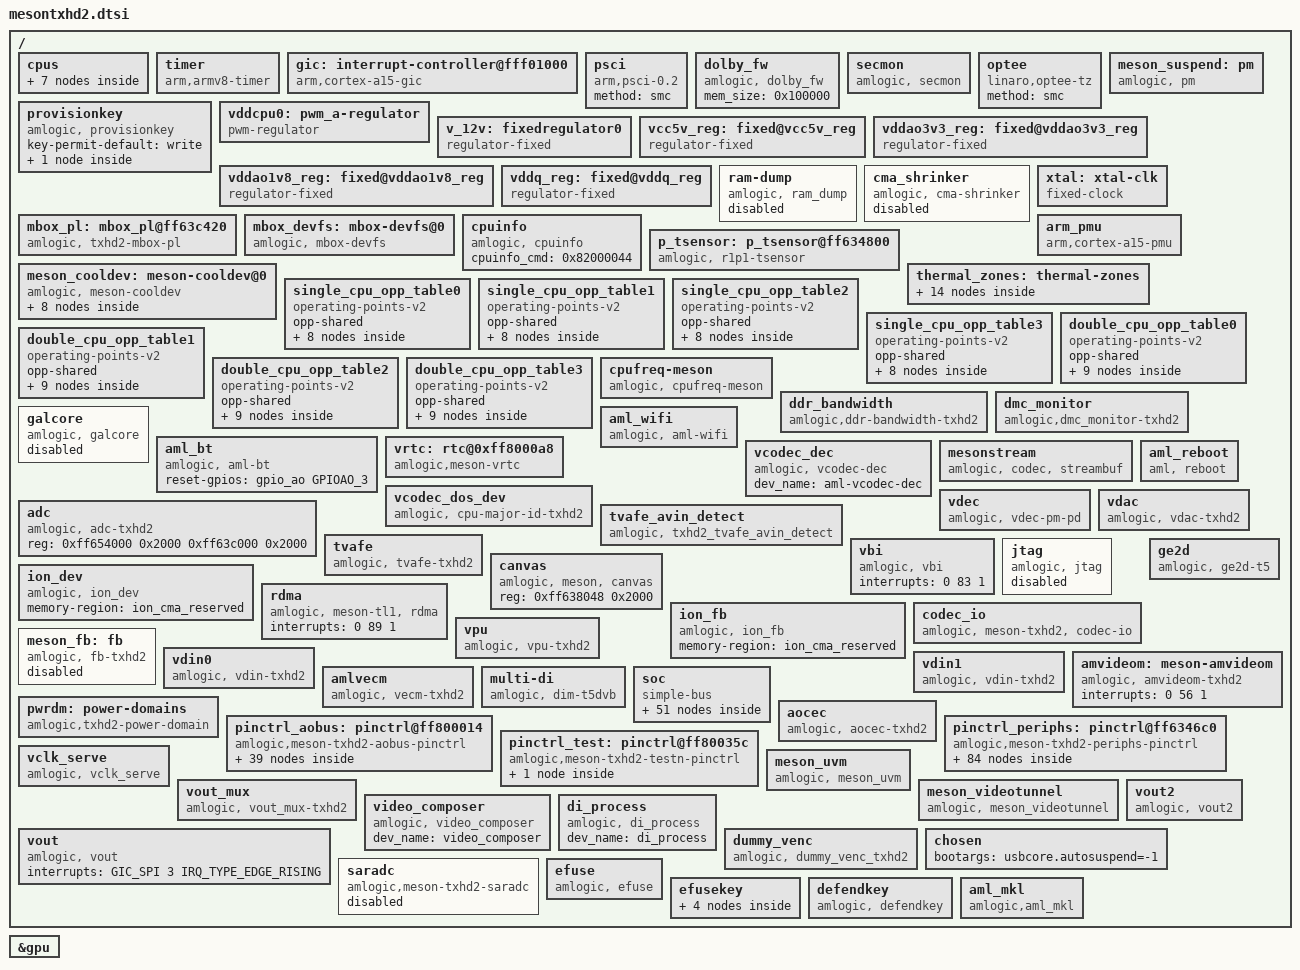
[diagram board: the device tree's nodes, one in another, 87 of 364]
// SPDX-License-Identifier: (GPL-2.0+ OR MIT)
/*
 * Copyright (c) 2021 Amlogic, Inc. All rights reserved.
 */

#include <dt-bindings/interrupt-controller/irq.h>
#include <dt-bindings/interrupt-controller/arm-gic.h>
#include <dt-bindings/power/txhd2-pd.h>
#include <dt-bindings/clock/txhd2-clkc.h>
#include <dt-bindings/clock/txhd2-aoclkc.h>
#include <dt-bindings/mailbox/txhd2-mbox.h>
#include <dt-bindings/gpio/gpio.h>
#include <dt-bindings/gpio/meson-txhd2-gpio.h>
#include <dt-bindings/pwm/pwm.h>
#include <dt-bindings/pwm/meson.h>
#include <dt-bindings/input/input.h>
#include <dt-bindings/input/meson_ir.h>
#include <dt-bindings/iio/adc/amlogic-saradc.h>
#include "meson-ir-map.dtsi"
#include <dt-bindings/thermal/thermal.h>
#include <dt-bindings/hwspinlock/amlogic,hwspinlock.h>
#include <dt-bindings/reset/amlogic,meson-txhd2-reset.h>
#include "mesongxbb-gpu-mali450.dtsi"

/ {
	cpus:cpus {
		#address-cells = <1>;
		#size-cells = <0>;

		CPU0:cpu@0 {
			device_type = "cpu";
			compatible = "arm,cortex-a53","arm,armv8";
			reg = <0x0>;
			enable-method = "psci";
			cpu-idle-states = <&CPU_SLEEP_0 &SYSTEM_SLEEP_0>;
			#cooling-cells = <2>;
			clocks = <&clkc CLKID_CPU_CLK>,
				<&clkc CLKID_CPU_CLK_DYN>,
				<&clkc CLKID_SYS_PLL>;
			clock-names = "core_clk",
				"low_freq_clk_parent",
				"high_freq_clk_parent";
			multi_tables_available;
			cpu-supply = <&vddcpu0>;
			voltage-tolerance = <0>;
			clock-latency = <50000>;
			dynamic-power-coefficient = <230>;
		};

		CPU1:cpu@1{
			device_type = "cpu";
			compatible = "arm,cortex-a53","arm,armv8";
			reg = <0x1>;
			enable-method = "psci";
			cpu-idle-states = <&CPU_SLEEP_0 &SYSTEM_SLEEP_0>;
			#cooling-cells = <2>;
//			clocks = <&clkc CLKID_CPU_CLK>,
//				<&clkc CLKID_CPU_DYN_CLK>,
//				<&clkc CLKID_SYS1_PLL>;
//			clock-names = "core_clk",
//				"low_freq_clk_parent",
//				"high_freq_clk_parent";
			multi_tables_available;
			voltage-tolerance = <0>;
			clock-latency = <50000>;
			dynamic-power-coefficient = <230>;
		};

		CPU2:cpu@2 {
			device_type = "cpu";
			compatible = "arm,cortex-a53","arm,armv8";
			reg = <0x2>;
			enable-method = "psci";
			cpu-idle-states = <&CPU_SLEEP_0 &SYSTEM_SLEEP_0>;
			#cooling-cells = <2>;
//			clocks = <&clkc CLKID_CPU_CLK>,
//				<&clkc CLKID_CPU_DYN_CLK>,
//				<&clkc CLKID_SYS1_PLL>;
//			clock-names = "core_clk",
//				"low_freq_clk_parent",
//				"high_freq_clk_parent";
			multi_tables_available;
			voltage-tolerance = <0>;
			clock-latency = <50000>;
			dynamic-power-coefficient = <230>;
		};

		CPU3:cpu@3 {
			device_type = "cpu";
			compatible = "arm,cortex-a53","arm,armv8";
			reg = <0x3>;
			enable-method = "psci";
			cpu-idle-states = <&CPU_SLEEP_0 &SYSTEM_SLEEP_0>;
			#cooling-cells = <2>;
//			clocks = <&clkc CLKID_CPU_CLK>,
//				<&clkc CLKID_CPU_DYN_CLK>,
//				<&clkc CLKID_SYS1_PLL>;
//			clock-names = "core_clk",
//				"low_freq_clk_parent",
//				"high_freq_clk_parent";
			multi_tables_available;
			voltage-tolerance = <0>;
			clock-latency = <50000>;
		};

		idle-states {
			entry-method = "arm,psci-0.2";
			CPU_SLEEP_0: cpu-sleep-0 {
					compatible = "arm,idle-state";
					arm,psci-suspend-param = <0x0010000>;
					local-timer-stop;
					entry-latency-us = <160>;
					exit-latency-us = <630>;
					min-residency-us = <1700>;
			};
			SYSTEM_SLEEP_0: system-sleep-0 {
					compatible = "arm,idle-state";
					arm,psci-suspend-param = <0x0000000>;
					entry-latency-us = <0x3fffffff>;
					exit-latency-us = <0x40000000>;
					min-residency-us = <0xffffffff>;
			};
		};
	};

	timer {
		compatible = "arm,armv8-timer";
		interrupts = <GIC_PPI 13 0xff08>,
				<GIC_PPI 14 0xff08>,
				<GIC_PPI 11 0xff08>,
				<GIC_PPI 10 0xff08>;
	};

	gic: interrupt-controller@fff01000 {
		compatible = "arm,cortex-a15-gic", "arm,cortex-a9-gic";
		#interrupt-cells = <3>;
		#address-cells = <0>;
		interrupt-controller;
		reg = <0xffc01000 0x1000>,
		      <0xffc02000 0x0100>;
		interrupts = <GIC_PPI 9 0xf04>;
	};

	psci {
		compatible = "arm,psci-0.2";
		method = "smc";
	};

	dolby_fw: dolby_fw {
		compatible = "amlogic, dolby_fw";
		mem_size = <0x100000>;
		status = "okay";
	};

	secmon {
		compatible = "amlogic, secmon";
		memory-region = <&secmon_reserved>;
		in_base_func = <0x82000020>;
		out_base_func = <0x82000021>;
		inout_size_func = <0x8200002a>;
		reserve_mem_size = <0x00300000>;
	};

	optee {
		compatible = "linaro,optee-tz";
		method = "smc";
	};

	provisionkey {
		compatible = "amlogic, provisionkey";
		status = "okay";
		key-permit-default = "write";
		//new key not need add dts if started with KEY_PROVISION_
		KEY_PROVISION_XXX { };
		//test_my_added_keyname { };
	};//End provisionkey

	meson_suspend:pm {
		compatible = "amlogic, pm";
		status = "okay";
		device_name = "aml_pm";
		extend_resume_reason;
		reg = <0xff8000a8 0x4>, /*SYSCTRL_STATUS_REG2*/
			<0xff6345cc 0x4>; /*SYSCTRL_STICKY_REG3*/
	};

	vddcpu0: pwm_a-regulator {
		compatible = "pwm-regulator";
		pwms = <&pwm_ab MESON_PWM_0 1500 0>;
		regulator-name = "vddcpu0";
		regulator-min-microvolt = <790000>;
		regulator-max-microvolt = <1150000>;
		regulator-always-on;
		max-duty-cycle = <1500>;
		/* Voltage Duty-Cycle */
		voltage-table = //<1150000 0>,//low:0x0024
				<1140000 0>,//0022
				<1130000 6>,//10021
				<1120000 8>,//20020
				<1110000 11>,//3001f
				<1100000 14>,//4001e
				<1090000 17>,//5001d
				<1080000 19>,//0006001c//
				<1070000 22>,//7001b
				<1060000 25>,//8001a
				<1050000 28>,//90019
				<1040000 31>,//a0018
				<1030000 33>,//b0017
				<1020000 36>,//c0016
				<1010000 39>,//0x00d00015
				<1000000 42>,//0x00e00014
				<990000 44>,//0x00f00013
				<980000 47>,//0x00100012
				<970000 50>,//0x00110011
				<960000 53>,//0x00120010
				<950000 56>,//0x0013000f
				<940000 58>,//0x0014000E
				<930000 61>,//0x0015000d
				<920000 64>,//0x0016000c
				<910000 67>,//0x0017000b
				<900000 69>,//0x0018000a
				<890000 72>,//0x00190009
				<880000 75>,//0x001a0008
				<870000 78>,//0x001b0007
				<860000 81>,//0x001c0006
				<850000 83>,//0x001d0005
				<840000 86>,//1e0004
				<830000 89>,//1f0003
				<820000 92>,//200002
				<810000 94>,//210001
				<800000 100>;//220000
				//<790000 100>;//high:0x240000
		status = "okay";
	};

	v_12v: fixedregulator0 {
		compatible = "regulator-fixed";
		regulator-name = "POWER_12V";
		regulator-min-microvolt = <12000000>;
		regulator-max-microvolt = <12000000>;
		regulator-boot-on;
		regulator-always-on;
	};

	vcc5v_reg: fixed@vcc5v_reg{
		vin-supply = <&v_12v>;
		compatible = "regulator-fixed";
		regulator-name = "VCC5V";
		regulator-min-microvolt = <5000000>;
		regulator-max-microvolt = <5000000>;
		gpio = <&gpio_ao GPIOAO_10 GPIO_ACTIVE_HIGH>;
		enable-active-high;
		regulator-boot-on;
		regulator-always-on;
	};

	vddao3v3_reg: fixed@vddao3v3_reg{
		vin-supply = <&v_12v>;
		compatible = "regulator-fixed";
		regulator-name = "VDDAO_3V3";
		regulator-min-microvolt = <3300000>;
		regulator-max-microvolt = <3300000>;
		regulator-boot-on;
		regulator-always-on;
	};

	vddao1v8_reg: fixed@vddao1v8_reg{
		vin-supply = <&vddao3v3_reg>;
		compatible = "regulator-fixed";
		regulator-name = "VDDAO_1V8";
		regulator-min-microvolt = <1800000>;
		regulator-max-microvolt = <1800000>;
		regulator-boot-on;
		regulator-always-on;
	};

	vddq_reg: fixed@vddq_reg{
		compatible = "regulator-fixed";
		vin-supply = <&v_12v>;
		regulator-name = "VDDQ";
		regulator-min-microvolt = <1218000>;
		regulator-max-microvolt = <1218000>;
		gpio = <&gpio_test GPIO_TEST_N GPIO_ACTIVE_HIGH>;
		enable-active-high;
		regulator-boot-on;
		regulator-always-on;
	};

	ram-dump {
		compatible = "amlogic, ram_dump";
		status = "disabled";
		reg = <0xFF6345E0   0x4>;
		reg-names = "SYSCTRL_STICKY_REG6";
		store_device = "data";
	};

	cma_shrinker: cma_shrinker {
		compatible = "amlogic, cma-shrinker";
		status = "disabled";
		adj  = <0 100 200 250 900 950>;
		free = <8192 12288 16384 24576 28672 32768>;
	};

	xtal: xtal-clk {
		compatible = "fixed-clock";
		clock-frequency = <24000000>;
		clock-output-names = "xtal";
		#clock-cells = <0>;
	};

	mbox_pl: mbox_pl@ff63c420 {
		status = "okay";
		compatible = "amlogic, txhd2-mbox-pl";
		reg = <0xfffc7400 0x200>, /*ao rx buf */
		      <0xff63c41C 0x4>,   /*ao rx set addr*/
		      <0xff63c424 0x4>,   /*ao rx clr addr*/
		      <0xff63c420 0x4>,   /*ao rx sts addr*/
		      <0xfffc7600 0x200>, /*ao tx buf */
		      <0xff63c428 0x4>,   /*ao tx set addr*/
		      <0xff63c430 0x4>,   /*ao tx clr addr*/
		      <0xff63c42C 0x4>;   /*ao tx sts addr*/
		interrupts = <GIC_SPI 210 IRQ_TYPE_EDGE_RISING>,
			     <GIC_SPI 136 IRQ_TYPE_EDGE_RISING>;
		#mbox-cells = <1>;
		mbox-tx = "rx", "tx";
		mbox-nums = <TXHD2_MBOX_NUMS>;
		mboxids = <TXHD2_MBOX_AO2REE>,
			  <TXHD2_MBOX_REE2AO>;
	};

	mbox_devfs: mbox-devfs@0 {
		status = "okay";
		compatible = "amlogic, mbox-devfs";
		mbox-nums = <1>;
		mbox-names = "ree2aocpu";
		mboxes = <&mbox_pl TXHD2_REE2AO_DEV>;
		mbox-dests = <MAILBOX_AOCPU>;
	};

	cpuinfo {
		compatible = "amlogic, cpuinfo";
		status = "okay";
		cpuinfo_cmd = <0x82000044>;
	};

	arm_pmu {
		compatible = "arm,cortex-a15-pmu";
		private-interrupts;
		interrupts = <GIC_SPI 237 IRQ_TYPE_LEVEL_HIGH>,
			     <GIC_SPI 238 IRQ_TYPE_LEVEL_HIGH>,
			     <GIC_SPI 239 IRQ_TYPE_LEVEL_HIGH>,
			     <GIC_SPI 240 IRQ_TYPE_LEVEL_HIGH>;
	};

	p_tsensor: p_tsensor@ff634800 {
		compatible = "amlogic, r1p1-tsensor";
		status = "okay";
		reg = <0xff634800 0x50>,
			<0xff800268 0x4>;
		tsensor_id = <0>;
		cal_type = <0x1>;
		cal_coeff = <361 461 2610 7243>;
		rtemp = <120000>;
		interrupts = <GIC_SPI 35 IRQ_TYPE_LEVEL_HIGH>;
		clocks = <&clkc CLKID_TS_CLK>; // CLKID_TS_COMP>;
		clock-names = "ts_comp";
		#thermal-sensor-cells = <1>;
		reset-names = "ts_rst";
		resets = <&reset RESET_TS_PLL>;
	};

	meson_cooldev: meson-cooldev@0 {
		status = "okay";
		compatible = "amlogic, meson-cooldev";
		cooling_devices {
			ddr_cool {
				ddr_reg = <0xff6384b4 0xff638224>; /*ddr gpu*/
				ddr_status = <13>;
				ddr_bits = <0 15>,
							<0 31>;
				ddr_data = <9616 9616 9616 7512 6010 4808 3756
				3434 3004 2404 2002 1716 1502 >;
				gpu_data = <0x28202820 0x28202820 0x28202820 0x28202820
					0x18101810 0x18101810 0x18101810 0x18101810 0x18101810
					0x02010201 0x02010201 0x02010201 0x02010201>;
				ddr_data1 = <9616 9616 9616 7512 6010 4808 3756
				3434 3004 2404 2002 1716 1502>;
				gpu_data1 = <0x28202820 0x28202820 0x28202820 0x28202820
					0x18101810 0x18101810 0x18101810 0x18101810 0x18101810
					0x02010201 0x02010201 0x02010201 0x02010201>;
				ddr_data2 = <9616 9616 9616 7512 6010 4808 3756
				3434 3004 2404 2002 1716 1502>;
				gpu_data2 = <0x28202820 0x28202820 0x28202820 0x28202820
					0x18101810 0x18101810 0x18101810 0x18101810 0x18101810
					0x02010201 0x02010201 0x02010201 0x02010201>;
				node_name = "ddr_cool0";
				device_type = "ddr";
			};
			cpucore_cool {
				cluster_core_num = <3>;
				cluster_cores = <1 2 3>;
				node_name = "cpucore";
				device_type = "cpucore";
			};
			gpufreq_cool {
				dyn_coeff = <245>;
				node_name = "bifrost";
				device_type = "gpufreq";
			};
			media_cool {
				node_name = "media_cool0";
				device_type = "media";
			};
		};
		ddr_cool0:ddr_cool0 {
			#cooling-cells = <2>; /* min followed by max */
		};
		cpucore:cpucore {
			#cooling-cells = <2>; /* min followed by max */
		};
		media_cool0:media_cool0 {
			#cooling-cells = <2>;
		};
	};/*meson cooling devices end*/

	thermal_zones: thermal-zones {
		soc_thermal: soc_thermal {
			polling-delay = <1000>;
			polling-delay-passive = <100>;
			sustainable-power = <1100>;
			thermal-sensors = <&p_tsensor 0>;
			trips {
				pswitch_on: trip-point@0 {
					temperature = <95000>;
					hysteresis = <5000>;
					type = "passive";
				};
				pcontrol: trip-point@1 {
					temperature = <105000>;
					hysteresis = <5000>;
					type = "passive";
				};
				pddr_change: trip-point@2 {
					temperature = <55000>;
					hysteresis = <5000>;
					type = "hot";
				};
				pcritical: trip-point@3 {
					temperature = <115000>;
					hysteresis = <1000>;
					type = "critical";
				};
				pmedia_change: trip-point@4 {
					temperature = <85000>;
					hysteresis = <10000>;
					type = "hot";
				};
				pcpucore: trip-point@5 {
					temperature = <95000>;
					hysteresis = <10000>;
					type = "hot";
				};
			};
			cooling-maps {
				cpufreq_cooling_map {
					trip = <&pcontrol>;
					cooling-device = <&CPU0 0 5>;
					contribution = <1024>;
				};
				ddr_cooling_map {
					trip = <&pddr_change>;
					cooling-device = <&ddr_cool0 0 2>;
					contribution = <1024>;
				};
				gpufreq_cooling_map {
					trip = <&pcontrol>;
					cooling-device = <&gpu 0 3>;
					contribution = <1024>;
				};
				media_cooling_map {
					trip = <&pmedia_change>;
					cooling-device = <&media_cool0 0 2>;
					contribution = <1024>;
				};
				cpucore_cooling_map {
					trip = <&pcpucore>;
					cooling-device = <&cpucore 0 2>;
					contribution = <1024>;
				};
			};
		};
	}; /*thermal zone end*/

	single_cpu_opp_table0: single_cpu_opp_table0 {
		compatible = "operating-points-v2";
		opp-shared;

		opp00 {
			opp-hz = /bits/ 64 <100000000>;
			opp-microvolt = <1020000>;
		};
		opp01 {
			opp-hz = /bits/ 64 <250000000>;
			opp-microvolt = <1020000>;
		};
		opp02 {
			opp-hz = /bits/ 64 <500000000>;
			opp-microvolt = <1020000>;
		};
		opp03 {
			opp-hz = /bits/ 64 <666666666>;
			opp-microvolt = <1020000>;
		};
		opp04 {
			opp-hz = /bits/ 64 <1000000000>;
			opp-microvolt = <1020000>;
		};
		opp05 {
			opp-hz = /bits/ 64 <1200000000>;
			opp-microvolt = <1070000>;
		};
		opp06 {
			opp-hz = /bits/ 64 <1296000000>;
			opp-microvolt = <1100000>;
		};
		opp07 {
			opp-hz = /bits/ 64 <1464000000>;
			opp-microvolt = <1130000>;
		};
	};

	single_cpu_opp_table1: single_cpu_opp_table1 {
		compatible = "operating-points-v2";
		opp-shared;

		opp00 {
			opp-hz = /bits/ 64 <100000000>;
			opp-microvolt = <1020000>;
		};
		opp01 {
			opp-hz = /bits/ 64 <250000000>;
			opp-microvolt = <1020000>;
		};
		opp02 {
			opp-hz = /bits/ 64 <500000000>;
			opp-microvolt = <1020000>;
		};
		opp03 {
			opp-hz = /bits/ 64 <666666666>;
			opp-microvolt = <1020000>;
		};
		opp04 {
			opp-hz = /bits/ 64 <1000000000>;
			opp-microvolt = <1020000>;
		};
		opp05 {
			opp-hz = /bits/ 64 <1200000000>;
			opp-microvolt = <1070000>;
		};
		opp06 {
			opp-hz = /bits/ 64 <1296000000>;
			opp-microvolt = <1100000>;
		};
		opp07 {
			opp-hz = /bits/ 64 <1464000000>;
			opp-microvolt = <1130000>;
		};
	};

	single_cpu_opp_table2: single_cpu_opp_table2 {
		compatible = "operating-points-v2";
		opp-shared;

		opp00 {
			opp-hz = /bits/ 64 <100000000>;
			opp-microvolt = <1000000>;
		};
		opp01 {
			opp-hz = /bits/ 64 <250000000>;
			opp-microvolt = <1000000>;
		};
		opp02 {
			opp-hz = /bits/ 64 <500000000>;
			opp-microvolt = <1000000>;
		};
		opp03 {
			opp-hz = /bits/ 64 <666666666>;
			opp-microvolt = <1000000>;
		};
		opp04 {
			opp-hz = /bits/ 64 <1000000000>;
			opp-microvolt = <1000000>;
		};
		opp05 {
			opp-hz = /bits/ 64 <1200000000>;
			opp-microvolt = <1060000>;
		};
		opp06 {
			opp-hz = /bits/ 64 <1296000000>;
			opp-microvolt = <1090000>;
		};
		opp07 {
			opp-hz = /bits/ 64 <1464000000>;
			opp-microvolt = <1110000>;
		};
	};

	single_cpu_opp_table3: single_cpu_opp_table3 {
		compatible = "operating-points-v2";
		opp-shared;

		opp00 {
			opp-hz = /bits/ 64 <100000000>;
			opp-microvolt = <980000>;
		};
		opp01 {
			opp-hz = /bits/ 64 <250000000>;
			opp-microvolt = <980000>;
		};
		opp02 {
			opp-hz = /bits/ 64 <500000000>;
			opp-microvolt = <980000>;
		};
		opp03 {
			opp-hz = /bits/ 64 <666666666>;
			opp-microvolt = <980000>;
		};
		opp04 {
			opp-hz = /bits/ 64 <1000000000>;
			opp-microvolt = <980000>;
		};
		opp05 {
			opp-hz = /bits/ 64 <1200000000>;
			opp-microvolt = <1000000>;
		};
		opp06 {
			opp-hz = /bits/ 64 <1296000000>;
			opp-microvolt = <1030000>;
		};
		opp07 {
			opp-hz = /bits/ 64 <1464000000>;
			opp-microvolt = <1060000>;
		};
	};

	double_cpu_opp_table0: double_cpu_opp_table0 {
		compatible = "operating-points-v2";
		opp-shared;

		opp00 {
			opp-hz = /bits/ 64 <100000000>;
			opp-microvolt = <1000000>;
		};
		opp01 {
			opp-hz = /bits/ 64 <250000000>;
			opp-microvolt = <1000000>;
		};
		opp02 {
			opp-hz = /bits/ 64 <500000000>;
			opp-microvolt = <1000000>;
		};
		opp03 {
			opp-hz = /bits/ 64 <666666666>;
			opp-microvolt = <1000000>;
		};
		opp04 {
			opp-hz = /bits/ 64 <1000000000>;
			opp-microvolt = <1000000>;
		};
		opp05 {
			opp-hz = /bits/ 64 <1200000000>;
			opp-microvolt = <1050000>;
		};
		opp06 {
			opp-hz = /bits/ 64 <1296000000>;
			opp-microvolt = <1080000>;
		};
		opp07 {
			opp-hz = /bits/ 64 <1416000000>;
			opp-microvolt = <1110000>;
		};
		opp08 {
			opp-hz = /bits/ 64 <1512000000>;
			opp-microvolt = <1130000>;
		};
	};

	double_cpu_opp_table1: double_cpu_opp_table1 {
		compatible = "operating-points-v2";
		opp-shared;

		opp00 {
			opp-hz = /bits/ 64 <100000000>;
			opp-microvolt = <1000000>;
		};
		opp01 {
			opp-hz = /bits/ 64 <250000000>;
			opp-microvolt = <1000000>;
		};
		opp02 {
			opp-hz = /bits/ 64 <500000000>;
			opp-microvolt = <1000000>;
		};
		opp03 {
			opp-hz = /bits/ 64 <666666666>;
			opp-microvolt = <1000000>;
		};
		opp04 {
			opp-hz = /bits/ 64 <1000000000>;
			opp-microvolt = <1000000>;
		};
		opp05 {
			opp-hz = /bits/ 64 <1200000000>;
			opp-microvolt = <1050000>;
		};
		opp06 {
			opp-hz = /bits/ 64 <1296000000>;
			opp-microvolt = <1080000>;
		};
		opp07 {
			opp-hz = /bits/ 64 <1416000000>;
			opp-microvolt = <1110000>;
		};
		opp08 {
			opp-hz = /bits/ 64 <1512000000>;
			opp-microvolt = <1130000>;
		};
	};

	double_cpu_opp_table2: double_cpu_opp_table2 {
		compatible = "operating-points-v2";
		opp-shared;

		opp00 {
			opp-hz = /bits/ 64 <100000000>;
			opp-microvolt = <980000>;
		};
		opp01 {
			opp-hz = /bits/ 64 <250000000>;
			opp-microvolt = <980000>;
		};
		opp02 {
			opp-hz = /bits/ 64 <500000000>;
			opp-microvolt = <980000>;
		};
		opp03 {
			opp-hz = /bits/ 64 <666666666>;
			opp-microvolt = <980000>;
		};
		opp04 {
			opp-hz = /bits/ 64 <1000000000>;
			opp-microvolt = <980000>;
		};
		opp05 {
			opp-hz = /bits/ 64 <1200000000>;
			opp-microvolt = <1040000>;
		};
		opp06 {
			opp-hz = /bits/ 64 <1296000000>;
			opp-microvolt = <1070000>;
		};
		opp07 {
			opp-hz = /bits/ 64 <1416000000>;
			opp-microvolt = <1090000>;
		};
		opp08 {
			opp-hz = /bits/ 64 <1512000000>;
			opp-microvolt = <1110000>;
		};
	};

	double_cpu_opp_table3: double_cpu_opp_table3 {
		compatible = "operating-points-v2";
		opp-shared;

		opp00 {
			opp-hz = /bits/ 64 <100000000>;
			opp-microvolt = <960000>;
		};
		opp01 {
			opp-hz = /bits/ 64 <250000000>;
			opp-microvolt = <960000>;
		};
		opp02 {
			opp-hz = /bits/ 64 <500000000>;
			opp-microvolt = <960000>;
		};
		opp03 {
			opp-hz = /bits/ 64 <666666666>;
			opp-microvolt = <960000>;
		};
		opp04 {
			opp-hz = /bits/ 64 <1000000000>;
			opp-microvolt = <960000>;
		};
		opp05 {
			opp-hz = /bits/ 64 <1200000000>;
			opp-microvolt = <980000>;
		};
		opp06 {
			opp-hz = /bits/ 64 <1296000000>;
			opp-microvolt = <1010000>;
		};
		opp07 {
			opp-hz = /bits/ 64 <1416000000>;
			opp-microvolt = <1040000>;
		};
		opp08 {
			opp-hz = /bits/ 64 <1512000000>;
			opp-microvolt = <1060000>;
		};
	};

	cpufreq-meson {
		compatible = "amlogic, cpufreq-meson";
		status = "okay";
	};

	ddr_bandwidth {
		compatible = "amlogic,ddr-bandwidth-txhd2";
		status = "okay";
		reg = <0xff638000 0x400
		       0xff6388a8 0x4>;
		interrupts = <0 52 IRQ_TYPE_LEVEL_HIGH>;
		interrupt-names = "ddr_bandwidth";
	};

	dmc_monitor {
		compatible = "amlogic,dmc_monitor-txhd2";
		status = "okay";
		memory-region = <&dmc_reserved>;
		reg = <0xff638000 0x400>;
		reg_base = <0xff639000>;
		interrupts = <0 52 IRQ_TYPE_LEVEL_HIGH>;
	};
	galcore {
		compatible = "amlogic, galcore";
		dev_name = "galcore";
		status = "disabled";
		//clocks = <&clkc CLKID_CTS_NNA_AXI_CLK>,
		//      <&clkc CLKID_CTS_NNA_CORE_CLK>,
		//      <&clkc CLKID_SYS1_PLL>;
		//clock-names = "cts_vipnanoq_axi_clk_composite",
		//      "cts_vipnanoq_core_clk_composite",
		//      "sys1_pll";
		//assigned-clocks =  <&clkc CLKID_SYS1_PLL>;
		assigned-clock-rates =  <1704000000>;
		interrupts = <0 59 4>;
		interrupt-names = "galcore";
		//power-domains = <&pwrdm PDID_T3_NNA>;
		reg = <0x0 0xfdb00000 0x0 0x40000
		      0x0 0xfe090000 0x0 0x2000
		      0x0 0xfe00c0a4 0x0 0x4
		      0x0 0xfe00c0a8 0x0 0x4
		      0x0 0xfe00c034 0x0 0x4
		      0X0 0xfe000220 0X0 0x4>;
		reg-names = "NN_REG","NN_SRAM","NN_MEM0",
		      "NN_MEM1","NN_RESET","NN_CLK";
		nn_power_version = <5>;
	};

	aml_bt: aml_bt {
		compatible = "amlogic, aml-bt";
		status = "okay";
		reset-gpios = <&gpio_ao    GPIOAO_3 GPIO_ACTIVE_HIGH>;
	};

	aml_wifi: aml_wifi {
		compatible = "amlogic, aml-wifi";
		status = "okay";
		interrupt-gpios = <&gpio_ao  GPIOAO_4  GPIO_ACTIVE_HIGH>;
		power_on-gpios = <&gpio_ao   GPIOAO_5  GPIO_ACTIVE_HIGH>;
		irq_trigger_type = "IRQF_TRIGGER_LOW";
	};

	vrtc: rtc@0xff8000a8 {
		compatible = "amlogic,meson-vrtc";
		reg = <0xff8000a8 0x4>;
		status = "okay";
		mboxes = <&mbox_pl TXHD2_REE2AO_VRTC>;
	};

	vcodec_dec {
		compatible = "amlogic, vcodec-dec";
		dev_name = "aml-vcodec-dec";
		status = "okay";
	};

	mesonstream {
		compatible = "amlogic, codec, streambuf";
		dev_name = "mesonstream";
		clocks = <&clkc CLKID_CLK81>;
		clock-names = "clk_81";
		status = "okay";
	};

	vcodec_dos_dev: vcodec_dos_dev {
		compatible = "amlogic, cpu-major-id-txhd2";
		dev_name = "vcodec_dos_dev";
		status = "okay";
		reg = <0xff620000 0x10000>,
			<0xff638000 0x2000>;
		reg-names = "dosbus",
			"dmcbus";
		clocks = <&clkc CLKID_CLK81_PARSER
			&clkc CLKID_CLK81_DMUX
			&clkc CLKID_CLK81_AHB_ARB0
			&clkc CLKID_CLK81_DOS
			&clkc CLKID_VDEC
			&clkc CLKID_HEVCF>;
		clock-names = "parser_top",
			"demux",
			"ahbarb0",
			"vdec",
			"clk_vdec_mux",
			"clk_hevc_mux";
		assigned-clock-parents = <&clkc CLKID_VDEC_0>,
			<&clkc CLKID_HEVCF_0>;
		assigned-clocks = <&clkc CLKID_VDEC>,
			<&clkc CLKID_HEVCF>;
	};

	vdec {
		compatible = "amlogic, vdec-pm-pd";
		dev_name = "vdec.0";
		status = "okay";
		interrupts = <0 3 1
			0 23 1
			0 32 1
			0 43 1
			0 44 1
			0 45 1
			0 74 1>;
		interrupt-names = "vsync",
			"demux",
			"parser",
			"mailbox_0",
			"mailbox_1",
			"mailbox_2",
			"parser_b";
		power-domains = <&pwrdm PDID_DOS_VDEC>,
			<&pwrdm PDID_DOS_HEVC>;
		power-domain-names = "pwrc-vdec",
			"pwrc-hevc";
	};

	aml_reboot {
		compatible = "aml, reboot";
		sys_reset = <0x84000009>;
		sys_poweroff = <0x84000008>;
		dis_nb_cpus_in_shutdown;
		reg = <0xff80023c 0x4>; /* SEC_AO_SEC_SD_CFG15 */
		status = "okay";
	};

	vdac {
		compatible = "amlogic, vdac-txhd2";
		status = "okay";
	};

	adc: adc {
		compatible = "amlogic, adc-txhd2";
		status = "okay";
		reg = <0xff654000 0x2000 /* afe reg base */
			0xff63c000 0x2000 /* ana base */
			>;
	};

	tvafe_avin_detect: tvafe_avin_detect {
		compatible = "amlogic, txhd2_tvafe_avin_detect";
		status = "okay";
		device_mask = <1>;/*bit0:ch1;bit1:ch2*/
		reg = <0xffd00000 0xf0a0>; /* cvbs irq base */
		interrupts = <0 12 1>,
				<0 13 1>;
	};

	tvafe: tvafe {
		compatible = "amlogic, tvafe-txhd2";
		/*memory-region = <&tvafe_cma_reserved>;*/
		status = "okay";
		flag_cma = <1>;/*1:share with codec_mm;0:cma alone*/
		cma_size = <5>;/*MByte*/
		reg = <0xff654000 0x2000 /*tvafe reg base*/
			0xff63C000 0x2000>; /*hiu reg base*/
		reserve-iomap = "true";
		tvafe_id = <0>;
		//pinctrl-names = "default";
		/*!!particular sequence, no more and no less!!!*/
		tvafe_pin_mux = <
				3 /* TVAFE_CVBS_IN2, CVBS_IN0 = 0 */
				1 /* TVAFE_CVBS_IN0, CVBS_IN1 */
				2 /* TVAFE_CVBS_IN1, CVBS_IN2 */
				4 /* TVAFE_CVBS_IN3, CVBS_IN3 */
		>;
		clocks = <&clkc CLKID_CDAC_CLK>;
		clock-names = "vdac_clk_gate";
		cutwindow_val_h = <0 0 0 0 24>; /* level 0~4 */
		cutwindow_val_v = <4 8 14 16 24>;  /* level 0~4 */
	};

	vbi: vbi {
		compatible = "amlogic, vbi";
		status = "okay";
		interrupts = <0 83 1>;
	};

	jtag {
		compatible = "amlogic, jtag";
		status = "disabled";
		select = "disable"; /* disable/apao */
		interrupts = <GIC_SPI 208 IRQ_TYPE_EDGE_RISING>;
		pinctrl-names="jtag_a_pins", "jtag_b_pins";
		pinctrl-0=<&jtag_apao_pins>;
		pinctrl-1=<&jtag_apee_pins>;
	};

	canvas: canvas {
		compatible = "amlogic, meson, canvas";
		status = "okay";
		reg = <0xff638048 0x2000>;
	};

	ion_dev {
		compatible = "amlogic, ion_dev";
		memory-region = <&ion_cma_reserved>;
	};

	ion_fb {
		compatible = "amlogic, ion_fb";
		memory-region = <&ion_cma_reserved>;
	};

	codec_io: codec_io {
		compatible = "amlogic, meson-txhd2, codec-io";
		status = "okay";
		#address-cells=<1>;
		#size-cells=<1>;
		ranges;
		reg =<0xffd00000 0x100000>,
			<0xff620000 0x10000>,
			<0xff63c000 0x2000>,
			<0xff800000 0x10000>,
			<0xff900000 0x40000>,
			<0xff638000 0x2000>,
			<0xff630000 0x2000>;
		reg-names = "cbus",
			"dosbus",
			"hiubus",
			"aobus",
			"vcbus",
			"dmcbus",
			"efusebus";
	};

	rdma {
		compatible = "amlogic, meson-tl1, rdma";
		status = "okay";
		interrupts = <0 89 1>;
		interrupt-names = "rdma";
	};

	vpu: vpu {
		compatible = "amlogic, vpu-txhd2";
		status = "okay";
		clocks = <&clkc CLKID_VAPB_0>,
			<&clkc CLKID_VAPB_1>,
			<&clkc CLKID_VAPB>,
			<&clkc CLKID_VPU_0>,
			<&clkc CLKID_VPU_1>,
			<&clkc CLKID_VPU>;
		clock-names = "vapb_clk0",
			"vapb_clk1",
			"vapb_clk",
			"vpu_clk0",
			"vpu_clk1",
			"vpu_clk";
		reg = <0xff646000 0x200    /* clk */
			0xff644000 0x40     /* pwrctrl */
			0xff900000 0x40000>; /* vcbus */
		clk_level = <6>;
		/* 0: 24M       1: 100.0M    2: 166.7M    3: 200.0M    4: 250.0M */
		/* 5: 333.3M    6: 400.0M */
	};

	meson_fb: fb {
		compatible = "amlogic, fb-txhd2";
		memory-region = <&logo_reserved>;
		status = "disabled";
		interrupts = <0 3 1
				0 56 1
				0 89 1>;
		interrupt-names = "viu-vsync", "viu2-vsync", "rdma";
		/* uboot logo,fb0/fb1 memory size,if afbcd fb0=0x01851000*/
		display_mode_default = "1080p60hz";
		scale_mode = <1>;
		/** 0:VPU free scale 1:OSD free scale 2:OSD super scale */
		display_size_default = <1920 1080 1920 2160 32>;
		/*1920*1080*4*3 = 0x17BB000*/
		clocks = <&clkc CLKID_VPU>;
		clock-names = "vpu_clkc";
	};

	ge2d: ge2d {
		compatible = "amlogic, ge2d-t5";
		status = "okay";
		interrupts = <0 146 1>;
		interrupt-names = "ge2d";
		clocks = <&clkc CLKID_VAPB>,
			<&clkc CLKID_GE2D>;
		clock-names = "clk_vapb_0",
			"clk_ge2d_gate";
		reg = <0xff940000 0x10000>;
	};

	/*if you want to use vdin just modify status to "ok"*/
	vdin0: vdin0 {/*common define*/
		compatible = "amlogic, vdin-txhd2";
		dev_name = "vdin0";
		/*status = "okay";*/
		/*memory-region = <&vdin0_cma_reserved>;*/
		reserve-iomap = "true";
		flag_cma = <0x101>;/*1:share with codec_mm;2:cma alone*/
		/*MByte, if 10bit disable: 64M(YUV422),
		 *if 10bit enable: 64*1.5 = 96M(YUV422)
		 *if support 4K2K-YUV444-10bit-WR:3840*2160*4*4 ~= 128M
		 *if support 4K2K-YUV422-10bit-wr:3840*2160*3*4 ~= 96M
		 *if support 4K2K-YUV422-8BIT-WR:3840*2160*2*4 ~= 64M
		 *if support 1080p-YUV422-8BIT-WR:1920*1080*2*4 ~= 16M
		 * onebuffer:
		 * worst case:(4096*2160*3 + 2M(afbce issue)) = 27.5M
		 * dw:960x540x3 = 1.5M
		 * total size:(27.5+1.5)x buffernumber
		 */
		/*cma_size = <174>;*/
		/*frame_buff_num = <6>;*/
		interrupts = <0 83 1 /* vdin0 vsync */
				/*0 214 1*/ /* vdin1 write down*/
				/*0 206 1*/ /* vpu crash */
				/*0 213 1*/>; /* vdin0 write down*/
		interrupt-names = "vsync_int"
				/*"mif2_meta_wr_done_int"*/
				/*"vpu_crash_int",*/
				/*"write_done_int"*/;
		rdma-irq = <2>;
		clocks = <&clkc CLKID_FCLK_DIV5>, <&clkc CLKID_VDIN_MEAS>;
			clock-names = "fclk_div5", "cts_vdin_meas_clk";
		vdin_id = <0>;
		/*vdin write mem color depth support:
		 * bit0:support 8bit
		 * bit1:support 9bit
		 * bit2:support 10bit
		 * bit3:support 12bit
		 * bit4:support yuv422 10bit full pack mode (from txl new add)
		 * bit5:force yuv422 to yuv444 malloc (for vdin0 debug)
		 * bit8:use 8bit  at 4k_50/60hz_10bit
		 * bit9:use 10bit at 4k_50/60hz_10bit
		 * bit10: support 10bit when double write
		 */
		tv_bit_mode = <0x235>;
		/* afbce_bit_mode: (amlogic frame buff compression encoder)
		 * bit0 -- enable afbce
		 * bit1 -- enable afbce compression-lossy
		 * bit4 -- afbce for 4k
		 * bit5 -- afbce for 1080p
		 * bit6 -- afbce for 720p
		 * bit7 -- afbce for smaller resolution
		 */
		/* afbce_bit_mode = <0x13>; */
		/* chk_wr_done_en: enable write done check */
		chk_wr_done_en;
		/* urgent_en; */
		/* double_write_en; */
		/* vdin v4l2 */
		v4l_support_en = <0>;
		v4l_vd_num = <70>;
		/* v4l2 capability */
		driver   = "vdinvideo";
		card     = "mesontxhd2";
		bus_info = "vdin0 v4l2";
		version  = <0x20220120>;
		/* fe_ports refer to tvin.h */
		fe_ports = <0x00001001   /* CVBS1 */
			0x00004000   /* HDMI0 */
			0x00004001   /* HDMI1 */
			0x00004002>; /* HDMI2 */
		/* vdin v4l2 end */
	};

	vdin1: vdin1 {/*common define*/
		compatible = "amlogic, vdin-txhd2";
		dev_name = "vdin1";
		/*status = "disabled";*/
		reserve-iomap = "true";
		/*memory-region = <&vdin1_cma_reserved>;*/
		flag_cma = <0x100>;/*1:share with codec_mm;0:cma alone*/
		interrupts = <0 85 1>;
		interrupt-names = "vsync_int"/*, "vpu_crash_int",*/
				/*"write_done_int"*/;
		rdma-irq = <4>;
		/*clocks = <&clock CLK_FPLL_DIV5>,
		 *	<&clock CLK_VDIN_MEAS_CLK>;
		 *clock-names = "fclk_div5", "cts_vdin_meas_clk";
		 */
		vdin_id = <1>;
		tv_bit_mode = <0x15>;
		/* vdin v4l2 */
		v4l_support_en = <0>;
		v4l_vd_num = <71>;
		/* v4l2 capability */
		driver   = "vdinvideo";
		card     = "mesontxhd2";
		bus_info = "vdin1 v4l2";
		version  = <0x20220120>;
		/* fe_ports refer to tvin.h */
		fe_ports = <0x0000a002   /* WB0_VD1 */
			0x0000a003   /* WB0_VD2 */
			0x0000a004   /* WB0_OSD1 */
			0x0000a005   /* WB0_OSD2 */
			0x0000a006   /* WB0_VPP */
			0x0000a007   /* WB0_VDIN_BIST */
			0x0000a008>; /* WB0_POST_BLEND */
		/* vdin v4l2 end */
	};

	amvideom: meson-amvideom {
		compatible = "amlogic, amvideom-txhd2";
		status = "okay";
		interrupts = <0 56 1>;
		interrupt-names = "vsync";
	};

	amlvecm: amlvecm {
		compatible = "amlogic, vecm-txhd2";
		dev_name = "aml_vecm";
		clocks = <&clkc CLKID_VID_LOCK>;
		clock-names = "cts_vid_lock_clk";
	};

	multi-di {
		compatible = "amlogic, dim-t5dvb";
		status = "okay";
		/* 0:use reserved; 1:use cma; 2:use cma as reserved */
		flag_cma = <4>;//t5d unsupport 4K,di 1CH need 42M
		en_4k = <0>;
		keep_dec_vf = <0>;
		po_fmt = <0>;
		post_nub = <9>;
		//memory-region = <&di_reserved>;
		//memory-region = <&di_cma_reserved>;
		interrupts = <0 46 1
				0 40 1>;
		interrupt-names = "pre_irq", "post_irq";
		clocks = <&clkc CLKID_VPU_CLKB>,
			<&clkc CLKID_VPU>;
		clock-names = "t5_vpu_clkb_tmp_gate",
			"t5_vpu_clkb_gate";
		clock-range = <334 400>;
		/* buffer-size = <3621952>;(yuv422 8bit) */
		buffer-size = <4074560>;/*yuv422 fullpack*/
		/* reserve-iomap = "true"; */
		/* if enable nr10bit, set nr10bit-support to 1 */
		post-wr-support = <1>;
		nr10bit-support = <1>;
		nrds-enable = <1>;
		pps-enable = <1>;
		ponly_mode = <1>;
		prelink_en = <1>;
		bp_thd = <0>;
		/* add for t5d verb bypass mem 2 ~ 15 */
		t5db_nr_thd = <2>;
		t5db_afbcd_en = <1>;
		/* afbcd enable for t5db */
		sub_v = <1>;//sub version for tXHD2
	};

	soc {
		compatible = "simple-bus";
		#address-cells = <1>;
		#size-cells = <1>;
		ranges;

		cbus: cbus@ffd00000 {
			compatible = "simple-bus";
			reg = <0xffd00000 0x25000>;
			#address-cells = <1>;
			#size-cells = <1>;
			ranges = <0x0 0xffd00000 0x25000>;

			gpio_intc: interrupt-controller@f080 {
				compatible = "amlogic,meson-gpio-intc",
					     "amlogic,meson-txhd2-gpio-intc";
				reg = <0xf080 0x10>;
				interrupt-controller;
				#interrupt-cells = <2>;
				amlogic,channel-interrupts =
					<64 65 66 67 68 69 70 71>;
			};

			wdt: watchdog@0f0d0 {
				compatible = "amlogic,meson-gxbb-wdt";
				status = "okay";
				/* 0:userspace, 1:kernel */
				amlogic,feed_watchdog_mode = <1>;
				reg = <0xf0d0 0x10>;
				clocks = <&xtal>;
			};

			meson_clk_msr@18000 {
				compatible = "amlogic,meson-txhd2-clk-measure";
				reg = <0x18000 0x1c>;
				status = "okay";
			};

			i2c0: i2c@1f000 {
				compatible = "amlogic,meson-i2c";
				reg = <0x1f000 0x48>;
				interrupts = <GIC_SPI 21 IRQ_TYPE_EDGE_RISING>;
				#address-cells = <1>;
				#size-cells = <0>;
				clocks = <&clkc CLKID_CLK81_I2C>;
				clock-frequency = <100000>;
				status = "disabled";
			};

			i2c1: i2c@1e000  {
				compatible = "amlogic,meson-i2c";
				reg = <0x1e000 0x48>;
				interrupts = <GIC_SPI 214 IRQ_TYPE_EDGE_RISING>;
				#address-cells = <1>;
				#size-cells = <0>;
				clocks = <&clkc CLKID_CLK81_I2C>;
				clock-frequency = <100000>;
				status = "disabled";
			};

			i2c2: i2c@1d000  {
				compatible = "amlogic,meson-i2c";
				reg = <0x1d000 0x48>;
				interrupts = <GIC_SPI 215 IRQ_TYPE_EDGE_RISING>;
				#address-cells = <1>;
				#size-cells = <0>;
				clocks = <&clkc CLKID_CLK81_I2C>;
				clock-frequency = <100000>;
				status = "disabled";
			};

			i2c3: i2c@1c000 {
				compatible = "amlogic,meson-i2c";
				reg = <0x1c000 0x48>;
				interrupts = <GIC_SPI 39 IRQ_TYPE_EDGE_RISING>;
				#address-cells = <1>;
				#size-cells = <0>;
				clocks = <&clkc CLKID_CLK81_I2C>;
				clock-frequency = <100000>;
				status = "disabled";
			};

			pwm_ab: pwm@1b000 {
				compatible = "amlogic,meson-t5d-ee-pwm";
				reg = <0x1b000 0x20>;
				#pwm-cells = <3>;
				clocks = <&xtal>,
					<&xtal>,
					<&xtal>,
					<&xtal>;
				clock-names = "clkin0",
						"clkin1",
						"clkin2",
						"clkin3";
				/* default xtal 24m  clkin0-clkin2 and
				 * clkin1-clkin3 should be set the same
				 */
				status = "okay";
			};

			pwm_cd: pwm@1a000 {
				compatible = "amlogic,meson-t5d-ee-pwm";
				reg = <0x1a000 0x20>;
				#pwm-cells = <3>;
				clocks = <&xtal>,
					<&xtal>,
					<&xtal>,
					<&xtal>;
				clock-names = "clkin0",
						"clkin1",
						"clkin2",
						"clkin3";
				/* default xtal 24m  clkin0-clkin2 and
				 * clkin1-clkin3 should be set the same
				 */
				status = "disabled";
			};

			pwm_ef: pwm@19000 {
				compatible = "amlogic,meson-t5d-ee-pwm";
				reg = <0x19000 0x20>;
				#pwm-cells = <3>;
				clocks = <&xtal>,
					<&xtal>,
					<&xtal>,
					<&xtal>;
				clock-names = "clkin0",
						"clkin1",
						"clkin2",
						"clkin3";
				/* default xtal 24m  clkin0-clkin2 and
				 * clkin1-clkin3 should be set the same
				 */
				status = "disabled";
			};

			reset: reset-controller@1004 {
				compatible = "amlogic,meson-t5d-reset";
				reg = <0x1004 0x9C>;
				#reset-cells = <1>;
			};

			uart_A: serial@24000 {
				compatible = "amlogic, meson-uart";
				reg = <0x24000 0x18>;
				interrupts = <0 26 1>;
				status = "disabled";
				clocks = <&xtal &clkc CLKID_CLK81_UART0>;
				clock-names = "clk_uart", "clk_gate";
				xtal_tick_en = <1>;
				fifosize = < 128 >;
				pinctrl-names = "default";
				pinctrl-0 = <&a_uart_pins1>;
			};

			uart_B: serial@23000 {
				compatible = "amlogic, meson-uart";
				reg = <0x23000 0x18>;
				interrupts = <0 75 1>;
				status = "disabled";
				clocks = <&xtal &clkc CLKID_CLK81_UART1>;
				clock-names = "clk_uart", "clk_gate";
				xtal_tick_en = <1>;
				fifosize = < 64 >;
				pinctrl-names = "default";
				pinctrl-0 = <&b_uart_pins>;
			};

			uart_C: serial@22000 {
				compatible = "amlogic, meson-uart";
				reg = <0x22000 0x18>;
				interrupts = <0 93 1>;
				status = "disabled";
				clocks = <&xtal &clkc CLKID_CLK81_UART2>;
				clock-names = "clk_uart", "clk_gate";
				xtal_tick_en = <1>;
				fifosize = < 64 >;
				pinctrl-names = "default";
				pinctrl-0 = <&c_uart_pins>;
			};

			spicc0: spi@13000 {
				compatible = "amlogic,meson-g12-spicc";
				reg = <0x13000 0x58>;
				interrupts = <GIC_SPI 81 IRQ_TYPE_LEVEL_HIGH>;
				clocks = <&clkc CLKID_CLK81_SPICC0>,
					 <&clkc CLKID_SPICC0>;
				clock-names = "core", "async";
				#address-cells = <1>;
				#size-cells = <0>;
				status = "disabled";
			};

		}; /* end of cbus */

		aobus: aobus@ff800000 {
			compatible = "simple-bus";
			reg = <0xff800000 0xa000>;
			#address-cells = <1>;
			#size-cells = <1>;
			ranges = <0x0 0xff800000 0xa000>;

			dcon_led: dcon_led@0x1000 {
				compatible = "amlogic,led_unipolar_ctrl";
				reg = <0x1000 0x88>;
				interrupts = <GIC_SPI 199 IRQ_TYPE_LEVEL_HIGH>;
				status = "disabled";
			};

			uart_AO: serial@3000 {
				compatible = "amlogic, meson-uart";
				reg = <0x3000 0x18>;
				interrupts = <0 193 1>;
				status = "disabled";
				clocks = <&xtal &clkc_AO CLKID_AO_UART1>;
				clock-names = "clk_uart", "clk_gate";
				xtal_tick_en = <1>;
				fifosize = < 64 >;
				/* 0 not support; 1 support */
				support-sysrq = <1>;
			};

			uart_AO_B: serial@4000 {
				compatible = "amlogic, meson-uart";
				reg = <0x4000 0x18>;
				interrupts = <0 197 1>;
				status = "disabled";
				clocks = <&xtal &clkc_AO CLKID_AO_UART1>;
				clock-names = "clk_uart", "clk_gate";
				xtal_tick_en = <1>;
				fifosize = < 64 >;
				pinctrl-names = "default";
				pinctrl-0 = <&ao_b_uart_pins>;
			};

			i2c_AO: i2c@5000 {
				compatible = "amlogic,meson-i2c";
				reg = <0x5000 0x48>;
				interrupts = <GIC_SPI 195 IRQ_TYPE_EDGE_RISING>;
				#address-cells = <1>;
				#size-cells = <0>;
				clocks = <&clkc_AO CLKID_AO_I2C_MASTER>;
				clock-frequency = <100000>;
				status = "disabled";
			};

			pwm_AO_ab: pwm@7000 {
				compatible = "amlogic,meson-g12a-ao-pwm-ab";
				reg = <0x7000 0x20>;
				#pwm-cells = <3>;
				clocks = <&xtal>,
					<&xtal>,
					<&xtal>,
					<&xtal>;
				clock-names = "clkin0",
						"clkin1",
						"clkin2",
						"clkin3";
				/* default xtal 24m  clkin0-clkin2 and
				 * clkin1-clkin3 should be set the same
				 */
				status = "okay";
			};

			pwm_AO_cd: pwm@2000 {
				compatible = "amlogic,meson-g12a-ao-pwm-cd";
				reg = <0x7000 0x20>;
				#pwm-cells = <3>;
				clocks = <&xtal>,
					<&xtal>,
					<&xtal>,
					<&xtal>;
				clock-names = "clkin0",
						"clkin1",
						"clkin2",
						"clkin3";
				/* default xtal 24m  clkin0-clkin2 and
				 * clkin1-clkin3 should be set the same
				 */
				status = "disabled";
			};

			rti: sys-ctrl@0 {
				compatible = "amlogic,meson-gx-ao-sysctrl",
						"simple-mfd", "syscon";
				reg = <0x0 0x300>;
				#address-cells = <1>;
				#size-cells = <1>;
				ranges = <0x0 0x0 0x300>;

				clkc_AO: clock-controller@2 {
					compatible = "amlogic,txhd2-aoclkc";
					#clock-cells = <1>;
					clocks = <&xtal>;
					clock-names = "xtal";
					status = "okay";
				};
			};

			ir: ir@8000 {
				compatible = "amlogic, meson-ir";
				reg = <0x8040 0xA4>,
					<0x8000 0x20>;
				status = "disable";
				protocol = <REMOTE_TYPE_NEC>;
				interrupts = <GIC_SPI 196 IRQ_TYPE_EDGE_RISING>;
				map = <&custom_maps>;
				max_frame_time = <200>;
			};

			irblaster: meson-irblaster@14C {
				compatible = "amlogic, meson_irblaster";
				status = "disabled";
				reg = <0x14c 0x10>;
				#irblaster-cells = <2>;
				interrupts = <GIC_SPI 198 IRQ_TYPE_EDGE_RISING>;
			};
		};/* end of aobus */

		demux: demux {
			compatible = "amlogic, dmx";
			status = "okay";

			interrupts = <GIC_SPI 23 IRQ_TYPE_EDGE_RISING
				GIC_SPI 5 IRQ_TYPE_EDGE_RISING
				GIC_SPI 53 IRQ_TYPE_EDGE_RISING
				GIC_SPI 19 IRQ_TYPE_EDGE_RISING
				GIC_SPI 25 IRQ_TYPE_EDGE_RISING
				GIC_SPI 17 IRQ_TYPE_EDGE_RISING>;
			interrupt-names = "demux0_irq",
				"demux1_irq",
				"demux2_irq",
				"dvr0_irq",
				"dvr1_irq",
				"dvr2_irq";
		};

		periphs: periphs@ff634000 {
			compatible = "simple-bus";
			reg = <0xff634000 0x1000>;
			#address-cells = <1>;
			#size-cells = <1>;
			ranges = <0x0 0xff634000 0x1000>;
		};/* end of periphs */

		rng {
			compatible="amlogic,meson-rng";
			status="okay";
			#address-cells = <1>;
			#size-cells = <1>;
			reg=<0xff630218 0x4>;
			quality=/bits/ 16 <1000>;
		};

		aml_dma {
			compatible = "amlogic,aml_txlx_dma";
			reg = <0xff63e000 0x48>;
			interrupts = <0 180 1>;
			status = "disabled";

			aml_aes {
				compatible = "amlogic,aes_g12a_dma";
				dev_name = "aml_aes_dma";
				status = "okay";
			};

			aml_sha {
				compatible = "amlogic,sha_dma";
				dev_name = "aml_sha_dma";
				status = "okay";
			};

			aml_tdes {
				compatible = "amlogic,tdes_dma";
				dev_name = "aml_tdes_dma";
				status = "okay";
			};
		};

		hiubus: hiubus@ff63c000 {
			compatible = "simple-bus";
			reg = <0xff63c000 0x2000>;
			#address-cells = <1>;
			#size-cells = <1>;
			ranges = <0x0 0xff63c000 0x2000>;
		};/* end of hiubus*/

		clkc: clock-controller {
			compatible = "amlogic,txhd2-clkc";
			reg = <0xff646000 0x3e0>,
			      <0xff63c000 0x3fc>;
			reg-names = "basic", "cpu";
			#clock-cells = <1>;
			clocks = <&xtal>;
			clock-names = "xtal";
			status = "okay";
		};

		sd_emmc_c: mmc@ffe07000 {
			compatible = "amlogic,meson-axg-mmc";
			reg = <0xffe07000 0x800>,
				<0xff64625c 0x4>,
				<0xff6346c0 0x4>;
			interrupts = <GIC_SPI 191 IRQ_TYPE_EDGE_RISING>;
			status = "disabled";
			clocks = <&clkc CLKID_CLK81_SD_EMMC_C>,
					<&clkc CLKID_SD_EMMC_C_SEL>,
					<&clkc CLKID_SD_EMMC_C>,
					<&xtal>,
					<&clkc CLKID_GP0_PLL>,
					<&clkc CLKID_GP0_PLL>;
			clock-names = "core", "mux0", "mux1",
					"clkin0", "clkin1", "clkin2";
			no-sd;
			no-sdio;
			card_type = <1>;
			ignore_desc_busy;
			mmc_debug_flag;
			tx_delay = <32>;
			src_clk_rate = <1488000000>;
			mmc-hs400-enhanced-strobe;
			sd-clock-sample;
		//  resets = <&reset RESET_SD_EMMC_C>;
		};

		crg_phy_20: crgphy20@ffe09000 {
			compatible = "amlogic, amlogic-crg-drd-usb2";
			status = "disable";
			#phy-cells = <0>;
			reg = <0xFFE09000 0x20
					0xFFD01008 0x100
					0xFF636000 0x2000>;
			pll-setting-1 = <0x040a06f4>;
			pll-setting-2 = <0x00000022>;
			pll-setting-3 = <0xac5f69e5>;
			pll-setting-4 = <0xbe18>;
			pll-setting-5 = <0x7>;
			pll-setting-6 = <0x78000>;
			pll-setting-7 = <0xe0004>;
			pll-setting-8 = <0xe000c>;
			dis-thred-enhance = <0x2>;/**t7-0x38:bit[26-27]**/
			pll-version = <1>;
			version = <3>;
			phy0-reset-level-bit = <16>;
			usb-reset-bit = <2>;
			reset-level = <0x84>;
			pwr-ctl = <0>;
			clocks = <&clkc CLKID_CLK81_USB_GENERAL>;
			clock-names = "crg_general";
			phy-id = <0>;
			usb-phy-trim-reg = <0xFF800270>;
		};

		crg3_phy_20: crg3phy20@ffe09080 {
			compatible = "amlogic, amlogic-crg-drd-usb3";
			status = "disable";
			#phy-cells = <0>;
			reg = <0xFFE09080 0x20>;
			phy1-reg = <0xFFE09080>;
			phy1-reg-size = <0x2000>;
			reset-reg = <0xFFD01008>;
			reset-reg-size = <0x100>;
			reset-level = <0x84>;
			phy-id = <0>;
		};

		crg20_otg: crg20otg@ffe09000 {
			compatible = "amlogic, amlogic-crg-otg";
			status = "disabled";
			usb2-phy-reg = <0xFFE09000>;
			usb2-phy-reg-size = <0x80>;
			usb3-phy-reg = <0xFFE09080>;
			usb3-phy-reg-size = <0x20>;
			interrupts = <0 20 IRQ_TYPE_EDGE_RISING>;
			//regulator = <1>;
		};

		crg20_drd: crg20drd@ff690000 {
			status = "disabled";
			reg = <0xFF690000 0x10000>;
			interrupts = <0 31 IRQ_TYPE_EDGE_RISING>;
			usb-phy = <&crg_phy_20>, <&crg3_phy_20>;
			cpu-type = "gxl";
			clock-src = "usb3.0";
			clocks = <&clkc CLKID_CLK81_USB_GENERAL>;
			clock-names = "crg_general";
			wr-outstanding-tune = <1>;
		};

		crg_udc_2: crgudc2@0xff690000 {
			compatible = "amlogic, crg_udc";
			status = "disable";
			device_name = "crg_udc_2";
			reg = <0xFF690000 0x10000>;
			interrupts = <0 31 IRQ_TYPE_EDGE_RISING>;
			clock-src = "usb0"; /** clock src */
			port-speed = <3>; /** 0: default, high, 1: full */
			phy-reg = <0xFFE09000>;
			phy-reg-size = <0xA0>;
			clocks = <&clkc CLKID_CLK81_USB_GENERAL>;
			clock-names = "usb_general";
			phy-id = <0>;
			version = <1>;
		};

		crg_phy_21: crgphy21@ffdf8000 {
			compatible = "amlogic, amlogic-crg-drd-usb2";
			status = "disable";
			#phy-cells = <0>;
			reg = <0xFFDF8000 0x40
					0xFFD01008 0x100
					0xFF63A000 0x2000
					0xFF658000 0x2000>;
			pll-setting-1 = <0x040a06f4>;
			pll-setting-2 = <0x00000022>;
			pll-setting-3 = <0xac5f69e5>;
			pll-setting-4 = <0xbe18>;
			pll-setting-5 = <0x7>;
			pll-setting-6 = <0x78000>;
			pll-setting-7 = <0xe0004>;
			pll-setting-8 = <0xe000c>;
			dis-thred-enhance = <0x2>;/**t7-0x38:bit[26-27]**/
			pll-version = <1>;
			version = <3>;
			phy0-reset-level-bit = <17>;
			phy1-reset-level-bit = <18>;
			usb-reset-bit = <2>;
			reset-level = <0x84>;
			pwr-ctl = <0>;
			clocks = <&clkc CLKID_CLK81_USB_GENERAL>;
			clock-names = "crg_general";
			phy-id = <1>;
			usb-phy-trim-reg = <0xFF800270>;
		};

		crg3_phy_21: crg3phy21@ffdf8080 {
			compatible = "amlogic, amlogic-crg-drd-usb3";
			status = "disable";
			#phy-cells = <0>;
			reg = <0xFFDF8080 0x20>;
			phy1-reg = <0xFFE09080>;
			phy1-reg-size = <0x20>;
			reset-reg = <0xFFD01008>;
			reset-reg-size = <0x100>;
			reset-level = <0x84>;
			phy-id = <1>;
		};

		crg2_drd: crg2drd@ffdf0000 {
			status = "disable";
			reg = <0xFFDF0000 0x10000>;
			interrupts = <0 30 IRQ_TYPE_EDGE_RISING>;
			usb-phy = <&crg_phy_21>, <&crg3_phy_21>;
			cpu-type = "gxl";
			clock-src = "usb3.0";
			clocks = <&clkc CLKID_CLK81_USB_GENERAL>;
			clock-names = "crg_general";
		};

		ethmac: ethernet@ff3f0000 {
			compatible = "amlogic,meson-axg-dwmac",
				     "snps,dwmac-3.70a",
				     "snps,dwmac";
			reg = <0xff3f0000 0x10000>,
			      <0xff650000 0x8>;
			interrupts = <GIC_SPI 8 IRQ_TYPE_LEVEL_HIGH>;
			interrupt-names = "macirq";
//			power-domains = <&pwrdm PDID_SC2_ETH>;
			clocks = <&clkc CLKID_CLK81_ETH_PHY>,
				 <&clkc CLKID_FCLK_DIV2>,
				 <&clkc CLKID_MPLL_50M>;
			clock-names = "stmmaceth", "clkin0", "clkin1";
			rx-fifo-depth = <4096>;
			tx-fifo-depth = <2048>;
			mboxes = <&mbox_pl TXHD2_REE2AO_ETH>;
			status = "disabled";
			analog_version = <1>;

			mdio0: mdio {
				#address-cells = <1>;
				#size-cells = <0>;
				compatible = "snps,dwmac-mdio";
			};
		};

		eth_phy: mdio-multiplexer@ff652000 {
			compatible = "amlogic,g12a-mdio-mux";
			reg = <0xFF652000 0xa4>;

			clocks = <&clkc CLKID_CLK81_ETH_PHY>,
				 <&xtal>,
				 <&clkc CLKID_MPLL_50M>;
			clock-names = "pclk", "clkin0", "clkin1";
			mdio-parent-bus = <&mdio0>;
			#address-cells = <1>;
			#size-cells = <0>;
			enet_type = <5>;
			phy_pll_mode = <1>;
			phy_mode = <2>;
			tx_amp_src = <0xFF800270>;

			ext_mdio: mdio@0 {
				reg = <0>;
				#address-cells = <1>;
				#size-cells = <0>;
			};

			int_mdio: mdio@1 {
				reg = <1>;
				#address-cells = <1>;
				#size-cells = <0>;

				internal_ephy: ethernet_phy@8 {
					compatible = "ethernet-phy-id0180.3301",
						     "ethernet-phy-ieee802.3-c22";
					interrupts = <GIC_SPI 9 IRQ_TYPE_LEVEL_HIGH>;
					reg = <8>;
					max-speed = <100>;
				};
			};
		};

	}; /* end of soc*/

	pwrdm: power-domains {
		compatible = "amlogic,txhd2-power-domain";
		#power-domain-cells = <1>;
		status = "okay";
	};

	aocec: aocec {
		compatible = "amlogic, aocec-txhd2";
		dev_name = "aocec";
		status = "okay";
		vendor_name = "Amlogic"; /* Max Chars: 8     */
		/* Refer to the following URL at:
		 * http://standards.ieee.org/develop/regauth/oui/oui.txt
		 */
		vendor_id = <0x000000>;
		product_desc = "TXHD2"; /* Max Chars: 16    */
		cec_osd_string = "AML_TV"; /* Max Chars: 14    */
		cec_version = <5>;/*5:1.4;6:2.0*/
		port_num = <2>;
		output = <0>;
		cec_sel = <1>;/*1:use one ip, 2:use 2 ip*/
		ee_cec; /*use cec a or b*/
		arc_port_mask = <0x1>;
		interrupts = <GIC_SPI 203 IRQ_TYPE_EDGE_RISING>;/*0:snps*/
		interrupt-names = "hdmi_aocecb";
		pinctrl-names = "default","hdmitx_aocecb","cec_pin_sleep";
		pinctrl-0=<&cec_b>;
		pinctrl-1=<&cec_b>;
		pinctrl-2=<&cec_b>;
		clocks = <&clkc_AO CLKID_CECB_32K_CLKOUT>;
		clock-names = "cecb_clk";
		reg = <0xff800000 0x2000
		       0xff634400 0x2000
		       0xff646000 0x2000
		       0xff634400 0x2000>;
		reg-names = "ao","periphs","clock", "pad";
		mbox-names = "mbox_cec";
		mboxes = <&mbox_pl TXHD2_REE2AO_AOCEC>;
	};

	pinctrl_aobus: pinctrl@ff800014{
		compatible = "amlogic,meson-txhd2-aobus-pinctrl";
		#address-cells = <1>;
		#size-cells = <1>;
		ranges;

		gpio_ao: ao-bank@ff800014{
			reg = <0xff800014 0x008>,
			      <0xff800024 0x014>;
			reg-names = "mux","gpio";
			gpio-controller;
			#gpio-cells = <2>;
			gpio-ranges = <&pinctrl_aobus 0 0 14>;
			mux-expand-reg = <0xff6346f8>;
			mux-expand-name = "mux_e";
		};
		i2cAO_pins1:i2cAO_pins1 {
			mux {
				groups = "i2cm_ao_a_scl_ao4",
					"i2cm_ao_a_sda_ao5";
				function = "i2cm_ao_a";
				drive-strength-microamp = <3000>;
				bias-disable;
			};
		};
		i2cAO_pins2:i2cAO_pins2 {
			mux {
				groups = "i2cm_ao_a_scl_ao10",
					"i2cm_ao_a_sda_ao11";
				function = "i2cm_ao_a";
				drive-strength-microamp = <3000>;
				bias-disable;
			};
		};

		pwm_AO_a_pins1:pwm_AO_a_pins1 {
			mux {
				groups = "pwm_ao_a_ao3";
				function = "pwm_ao_a";
			};
		};
		pwm_AO_a_pins2:pwm_AO_a_pins2 {
			mux {
				groups = "pwm_ao_a_ao7";
				function = "pwm_ao_a";
			};
		};
		pwm_AO_b_pins1:pwm_AO_b_pins1 {
			mux {
				groups = "pwm_ao_b";
				function = "pwm_ao_b";
			};
		};
		pwm_AO_c_pins1:pwm_AO_c_pins1 {
			mux {
				groups = "pwm_ao_c_ao8";
				function = "pwm_ao_c";
			};
		};
		pwm_AO_c_pins2:pwm_AO_c_pins2 {
			mux {
				groups = "pwm_ao_c_ao12";
				function = "pwm_ao_c";
			};
		};
		pwm_AO_d_pins1:pwm_AO_d_pins1 {
			mux {
				groups = "pwm_ao_d_ao2";
				function = "pwm_ao_d";
			};
		};
		pwm_AO_d_pins2:pwm_AO_d_pins2 {
			mux {
				groups = "pwm_ao_d_ao13";
				function = "pwm_ao_d";
			};
		};

		dcon_led_pins1:dcon_led_pins1 {
			mux {
				groups = "dcon_led_ao6";
				function = "dcon_led";
				drive-strength-microamp = <3000>;
				bias-disable;
			};
		};

		dcon_led_pins2:dcon_led_pins2 {
			mux {
				groups = "dcon_led_ao7";
				function = "dcon_led";
				drive-strength-microamp = <3000>;
				bias-disable;
			};
		};

		dcon_led_pins3:dcon_led_pins3 {
			mux {
				groups = "dcon_led_ao8";
				function = "dcon_led";
				drive-strength-microamp = <3000>;
				bias-disable;
			};
		};
	};

	pinctrl_periphs: pinctrl@ff6346c0{
		compatible = "amlogic,meson-txhd2-periphs-pinctrl";
		#address-cells = <1>;
		#size-cells = <1>;
		ranges;

		gpio: banks@ff6346c0{
			reg = <0xff6346c0 0x040>,
			      <0xff6344e8 0x018>,
			      <0xff634520 0x018>,
			      <0xff634440 0x04c>;
			reg-names = "mux", "pull", "pull-enable", "gpio";
			gpio-controller;
			#gpio-cells = <2>;
			gpio-ranges = <&pinctrl_periphs 0 0 66>;
			mux-expand-reg = <0xff6346f8>;
			mux-expand-name = "mux_e";
		};

		emmc_pins: emmc_pins {
			mux-0 {
				groups = "emmc_d0",
						"emmc_d1",
						"emmc_d2",
						"emmc_d3",
						"emmc_d4",
						"emmc_d5",
						"emmc_d6",
						"emmc_d7",
						"emmc_cmd";
				function = "emmc";
				bias-pull-up;
			};

			mux-1 {
				groups = "emmc_clk";
				function = "emmc";
				bias-pull-up;
			};
		};

		emmc_ds_pins: emmc_ds_pins {
			mux {
				groups = "emmc_ds";
				function = "emmc";
				bias-pull-down;
			};
		};

		emmc_clk_gate_pins: emmc_clk_gate_pins {
			mux {
				groups = "GPIOB_8";
				function = "gpio_periphs";
				bias-pull-down;
			};
		};

		spicc0_pins_c: spicc0_pins_c {
			mux {
				groups = "spi_mosi_a_c8",
					"spi_miso_a_c9",
					//"spi_ss0_a_c7",used as GPIOC_7
					"spi_clk_a_c10";
				function = "spi";
				drive-strength-microamp = <3000>;
			};
		};

		spicc0_pins_dv: spicc0_pins_dv {
			mux {
				groups = "spi_miso_a_dv7",
					"spi_mosi_a_dv8",
					//"spi_ss0_a_dv6",used as GPIODV_6
					"spi_clk_a_dv9";
				function = "spi";
				drive-strength-microamp = <3000>;
			};
		};
	};

	pinctrl_test: pinctrl@ff80035c {
		compatible = "amlogic,meson-txhd2-testn-pinctrl";
		#address-cells = <1>;
		#size-cells = <1>;
		ranges;

		gpio_test: test-bank@ff80035c {
			reg = <0xff80037c 0x004>,
			      <0xff80035c 0x004>;
			reg-names = "mux", "gpio";
			gpio-controller;
			#gpio-cells = <2>;
			gpio-ranges = <&pinctrl_test 0 0 1>;
		};
	};

	vclk_serve: vclk_serve {
		compatible = "amlogic, vclk_serve";
		status = "okay";
		mode = <1>;
		reg = <0xff63c000 0x400 /* hiu reg */
			0xff646000 0x4a0>; /* clk reg */
	};

	vout_mux: vout_mux {
		compatible = "amlogic, vout_mux-txhd2";
		status = "okay";
		clocks = <&clkc CLKID_FCLK_DIV5>, <&clkc CLKID_VDIN_MEAS>;
		clock-names = "fclk_div5", "vdin_meas_clk";
	};

	meson_uvm {
			compatible = "amlogic, meson_uvm";
			status = "okay";
		};

	meson_videotunnel{
		compatible = "amlogic, meson_videotunnel";
		status = "okay";
	};

	video_composer {
		compatible = "amlogic, video_composer";
		dev_name = "video_composer";
		status = "okay";
	};

	di_process {
		compatible = "amlogic, di_process";
		dev_name = "di_process";
		status = "okay";
	};

	vout: vout {
		compatible = "amlogic, vout";
		status = "okay";
		interrupts = <GIC_SPI 3 IRQ_TYPE_EDGE_RISING>;
		interrupt-names = "vsync";
	};

	vout2: vout2 {
		compatible = "amlogic, vout2";
		status = "okay";
	};

	dummy_venc: dummy_venc {
		compatible = "amlogic, dummy_venc_txhd2";
		status = "okay";
	};

	chosen {
		bootargs = "usbcore.autosuspend=-1";
	};

	saradc: saradc {
		compatible = "amlogic,meson-txhd2-saradc";
		status = "disabled";
		#io-channel-cells = <1>;
		clocks = <&xtal>,
			 <&clkc_AO CLKID_AO_SAR_ADC>,
			 <&clkc_AO CLKID_SARADC_GATE>,
			 <&clkc_AO CLKID_SARADC_MUX>;
		clock-names = "clkin", "core", "adc_clk", "adc_sel";
		interrupts = <GIC_SPI 200 IRQ_TYPE_EDGE_RISING>;
		reg = <0xff809000 0x48>;
	};

	efuse: efuse {
		compatible = "amlogic, efuse";
		read_cmd = <0x82000030>;
		write_cmd = <0x82000031>;
		get_max_cmd = <0x82000033>;
		mem_in_base_cmd = <0x82000020>;
		mem_out_base_cmd = <0x82000021>;
		reg = <0xff800228 0x4>;
		secureboot_mask = <0x00000010>;
		key = <&efusekey>;
		clocks = <&clkc CLKID_CLK81_EFUSE>;
		clock-names = "efuse_clk";
		status = "okay";
	};

	efusekey: efusekey {
		keynum = <4>;
		key0 = <&key_0>;
		key1 = <&key_1>;
		key2 = <&key_2>;
		key3 = <&key_3>;
		key_0:key_0 {
			keyname = "mac";
			offset = <0>;
			size = <6>;
		};
		key_1:key_1 {
			keyname = "mac_bt";
			offset = <6>;
			size = <6>;
		};
		key_2:key_2 {
			keyname = "mac_wifi";
			offset = <12>;
			size = <6>;
		};
		key_3:key_3 {
			keyname = "usid";
			offset = <18>;
			size = <16>;
		};
	};

	defendkey: defendkey {
		compatible = "amlogic, defendkey";
		reg=<0xff800228 0x4>;
		memory-region = <&defendkey_reserved>;
		mem_size = <0x100000>;
		status = "okay";
	};

	aml_mkl: aml_mkl {
		compatible = "amlogic,aml_mkl";
		reg = <0xff630000 0x180>;
		kl_type = <0>;
		kl_vid_type = <0>;
		kl_offset = <0x80 0x100>;
		status = "okay";
	};
};

&pinctrl_aobus {
	remote_pins: remote_pin {
		mux {
			groups = "remote_input_ao6";
			function = "remote";
			bias-disable;
		};
	};

	remote_out_pins: remote_out_pins {
		mux {
			groups = "remote_out_ao6";
			function = "remote";
		};
	};

	remote_out_pins1: remote_out_pins1 {
		mux {
			groups = "remote_out_ao11";
			function = "remote";
		};
	};

	ao_b_uart_pins:ao_b_uart {
			mux {
				groups = "uart_tx_ao_b_ao4",
					 "uart_rx_ao_b_ao5";
				function = "uart_ao_b";
				drive-strength-microamp = <3000>;
				bias-pull-up;
			};
	};

	ao_b_uart_pins1:ao_b_uart1 {
			mux {
				groups = "uart_tx_ao_b_ao10",
					 "uart_rx_ao_b_ao11";
				function = "uart_ao_b";
				drive-strength-microamp = <3000>;
				bias-pull-up;
			};
	};

	jtag_apao_pins:jtag_apao_pin {
		mux {
			groups = "jtag_tdi_ao3",
			"jtag_tdo_ao4",
			"jtag_clk_ao5",
			"jtag_tms_ao7";
			function = "jtag_ao";
		};
	};

	cec_b: cec_b {
		mux {
			groups = "cec_ao_b_ao7";
			function = "cec_ao_b";
		};
	};
};

&pinctrl_periphs {
	jtag_apee_pins:jtag_apee_pin {
		mux {
			groups = "jtag_tdi_c1",
			"jtag_tdo_c0",
			"jtag_clk_c4",
			"jtag_tms_c5";
			function = "jtag";
		};
	};

	i2c0_pins1:i2c0_pins1 {
		mux {
			groups = "i2cm_a_sda_dv4",
				"i2cm_a_scl_dv5";
			function = "i2cm_a";
			drive-strength-microamp = <3000>;
			bias-disable;
		};
	};
	i2c0_pins2:i2c0_pins2 {
		mux {
			groups = "i2cm_a_scl_h4",
				"i2cm_a_sda_h5";
			function = "i2cm_a";
			drive-strength-microamp = <3000>;
			bias-disable;
		};
	};
	i2c0_pins3:i2c0_pins3 {
		mux {
			groups = "i2cm_a_sda_z6",
				"i2cm_a_scl_z7";
			function = "i2cm_a";
			drive-strength-microamp = <3000>;
			bias-disable;
		};
	};
	i2c1_pins1:i2c1_pins1 {
		mux {
			groups = "i2cm_b_sda_dv0",
				"i2cm_b_scl_dv1";
			function = "i2cm_b";
			drive-strength-microamp = <3000>;
			bias-disable;
		};
	};
	i2c1_pins2:i2c1_pins2 {
		mux {
			groups = "i2cm_b_sda_z0",
				"i2cm_b_scl_z1";
			function = "i2cm_b";
			drive-strength-microamp = <3000>;
			bias-disable;
		};
	};
	i2c2_pins1:i2c2_pins1 {
		mux {
			groups = "i2cm_c_sda_c2",
				"i2cm_c_scl_c3";
			function = "i2cm_c";
			drive-strength-microamp = <3000>;
			bias-disable;
		};
	};
	i2c2_pins2:i2c2_pins2 {
		mux {
			groups = "i2cm_c_scl_h8",
				"i2cm_c_sda_h9";
			function = "i2cm_c";
			drive-strength-microamp = <3000>;
			bias-disable;
		};
	};
	i2c3_pins1:i2c3_pins1 {
		mux {
			groups = "i2cm_d_scl_h0",
				"i2cm_d_sda_h1";
			function = "i2cm_d";
			drive-strength-microamp = <3000>;
			bias-disable;
		};
	};
	i2c3_pins2:i2c3_pins2 {
		mux {
			groups = "i2cm_d_scl_h10",
				"i2cm_d_sda_h11";
			function = "i2cm_d";
			drive-strength-microamp = <3000>;
			bias-disable;
		};
	};

	pwm_a_pins1:pwm_a_pins1 {
		mux {
			groups = "pwm_a_dv4";
			function = "pwm_a";
		};
	};
	pwm_a_pins2:pwm_a_pins2 {
		mux {
			groups = "pwm_a_h7";
			function = "pwm_a";
		};
	};
	pwm_a_pins3:pwm_a_pins3 {
		mux {
			groups = "pwm_a_z5";
			function = "pwm_a";
		};
	};
	pwm_a_pins4:pwm_a_pins4 {
		mux {
			groups = "pwm_a_z7";
			function = "pwm_a";
		};
	};

	pwm_b_pins1:pwm_b_pins1 {
		mux {
			groups = "pwm_b_c9";
			function = "pwm_b";
		};
	};
	pwm_b_pins2:pwm_b_pins2 {
		mux {
			groups = "pwm_b_z1";
			function = "pwm_b";
		};
	};

	pwm_c_pins1:pwm_c_pins1 {
		mux {
			groups = "pwm_c_c10";
			function = "pwm_c";
		};
	};
	pwm_c_pins2:pwm_c_pins2 {
		mux {
			groups = "pwm_c_h11";
			function = "pwm_c";
		};
	};
	pwm_c_pins3:pwm_c_pins3 {
		mux {
			groups = "pwm_c_z0";
			function = "pwm_c";
		};
	};

	pwm_d_pins1:pwm_d_pins1 {
		mux {
			groups = "pwm_d_dv2";
			function = "pwm_d";
		};
	};
	pwm_d_pins2:pwm_d_pins2 {
		mux {
			groups = "pwm_d_c6";
			function = "pwm_d";
		};
	};
	pwm_d_pins3:pwm_d_pins3 {
		mux {
			groups = "pwm_d_h9";
			function = "pwm_d";
		};
	};
	pwm_d_pins4:pwm_d_pins4 {
		mux {
			groups = "pwm_d_z2";
			function = "pwm_d";
		};
	};

	pwm_e_pins1:pwm_e_pins1 {
		mux {
			groups = "pwm_e_h8";
			function = "pwm_e";
		};
	};
	pwm_e_pins2:pwm_e_pins2 {
		mux {
			groups = "pwm_e_z4";
			function = "pwm_e";
		};
	};

	pwm_f_pins1:pwm_f_pins1 {
		mux {
			groups = "pwm_f";
			function = "pwm_f";
		};
	};

	dcon_led_pins4:dcon_led_pins4 {
		mux {
			groups = "dcon_led_z5";
			function = "dcon_led";
			drive-strength-microamp = <3000>;
			bias-disable;
		};
	};

	a_uart_pins:a_uart {
			mux {
				groups = "uart_rts_a_dv6",
					 "uart_cts_a_dv7",
					 "uart_tx_a_dv8",
					 "uart_rx_a_dv9";
				function = "uart_a";
				drive-strength-microamp = <3000>;
				bias-pull-up;
			};
	};

	a_uart_pins1:a_uart1 {
			mux {
				groups = "uart_rts_a_c10",
					 "uart_cts_a_c9",
					 "uart_tx_a_c8",
					 "uart_rx_a_c7";
				function = "uart_a";
				drive-strength-microamp = <3000>;
				bias-pull-up;
			};
	};

	a_uart_pins2:a_uart2 {
			mux {
				groups = "uart_tx_a_z6",
					 "uart_rx_a_z7";
				function = "uart_a";
				drive-strength-microamp = <3000>;
				bias-pull-up;
			};
	};

	b_uart_pins:b_uart {
			mux {
				groups = "uart_tx_b",
					 "uart_rx_b";
				function = "uart_b";
				drive-strength-microamp = <3000>;
				bias-pull-up;
			};
	};

	c_uart_pins:c_uart {
			mux {
				groups = "uart_tx_c",
					 "uart_rx_c";
				function = "uart_c";
				drive-strength-microamp = <3000>;
				bias-pull-up;
			};
	};

	hdmirx_a_mux:hdmirx_a_mux {
		mux {
			groups = "hdmirx_a_hpd",
				"hdmirx_a_5vdet",
				"hdmirx_a_sda",
				"hdmirx_a_scl";
			function = "hdmirx_a";
		};
	};

	hdmirx_b_mux:hdmirx_b_mux {
		mux {
			groups = "hdmirx_b_hpd",
				"hdmirx_b_5vdet",
				"hdmirx_b_sda",
				"hdmirx_b_scl";
			function = "hdmirx_b";
		};
	};

	lcd_tcon_mlvds_pins: lcd_tcon_mlvds_pin {
		mux {
			groups = "tcon_0","tcon_1","tcon_2","tcon_3",
				"tcon_4","tcon_5","tcon_6","tcon_8",
				"tcon_9","tcon_12";
			function = "tcon";
		};
	};

	lcd_tcon_mlvds_off_pins: lcd_tcon_mlvds_off_pin {
		mux {
			groups = "GPIOH_0","GPIOH_1","GPIOH_2","GPIOH_3",
				"GPIOH_4","GPIOH_5","GPIOH_6","GPIOH_8",
				"GPIOH_9","GPIOH_12";
			function = "gpio_periphs";
			input-enable;
		};
	};

};

&gpu{
	reg = <0xffe40000 0x40000>, /*mali APB bus base address*/
	      <0xffd01000 0x01000>, /*reset register*/
	      <0xfffb0000 0x01000>, /*aobus for gpu pmu domain*/
	      <0xff646000 0x01000>, /*hiubus for gpu clk cntl*/
	      <0xffd01000 0x01000>;
	interrupts = <0 160 4>, <0 161 4>, <0 162 4>, <0 163 4>,
		     <0 164 4>, <0 165 4>, <0 166 4>, <0 167 4>;
	interrupt-names = "IRQGP", "IRQGPMMU", "IRQPP", "IRQPMU",
			  "IRQPP0", "IRQPPMMU0", "IRQPP1", "IRQPPMMU1";
	pmu_domain_config = <0x1 0x2 0x4 0x0 0x0 0x0 0x0 0x0 0x0 0x1 0x2 0x0>;
	num_of_pp = <2> ;
	sc_mpp = <2>;/* number of pp used most of time.*/
	clocks = <&clkc CLKID_MALI>, <&clkc CLKID_GP0_PLL>;
	clock-names = "gpu_mux", "gp0_pll";

	tbl = <&clk125_cfg &clk285_cfg &clk400_cfg
		&clk500_cfg &clk666_cfg &clk744_cfg &clk744_cfg>;
};
